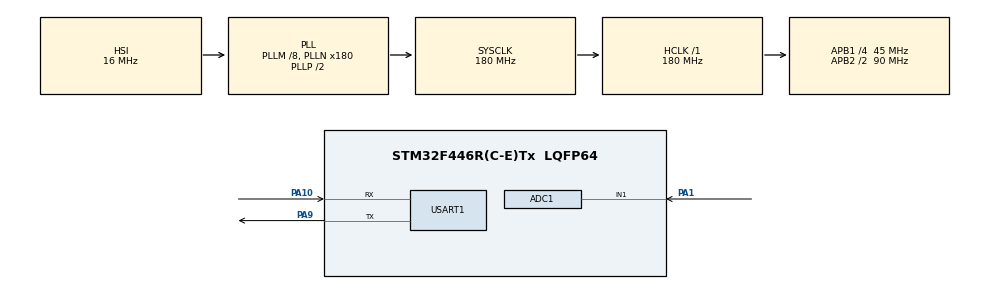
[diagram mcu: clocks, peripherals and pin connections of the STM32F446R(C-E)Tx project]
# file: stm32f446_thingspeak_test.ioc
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ADC1.Channel-0\#ChannelRegularConversion=ADC_CHANNEL_1
ADC1.NbrOfConversionFlag=1
ADC1.Rank-0\#ChannelRegularConversion=1
ADC1.SamplingTime-0\#ChannelRegularConversion=ADC_SAMPLETIME_3CYCLES
ADC1.master=1
Mcu.Family=STM32F4
Mcu.Name=STM32F446R(C-E)Tx
Mcu.Package=LQFP64
NVIC.PriorityGroup=NVIC_PRIORITYGROUP_4
NVIC.USART1_IRQn=true\:0\:0\:false\:false\:true\:true\:true
PA1.Signal=ADCx_IN1
PA10.Mode=Asynchronous
PA10.Signal=USART1_RX
PA9.Mode=Asynchronous
PA9.Signal=USART1_TX
PH0-OSC_IN.Mode=HSE-External-Clock-Source
PH0-OSC_IN.Signal=RCC_OSC_IN
PH1-OSC_OUT.Mode=HSE-External-Clock-Source
PH1-OSC_OUT.Signal=RCC_OSC_OUT
ProjectManager.HeapSize=0x200
ProjectManager.StackSize=0x400
ProjectManager.TargetToolchain=SW4STM32
RCC.AHBFreq_Value=180000000
RCC.APB1CLKDivider=RCC_HCLK_DIV4
RCC.APB1Freq_Value=45000000
RCC.APB1TimFreq_Value=90000000
RCC.APB2CLKDivider=RCC_HCLK_DIV2
RCC.APB2Freq_Value=90000000
RCC.APB2TimFreq_Value=180000000
RCC.CortexFreq_Value=180000000
RCC.HCLKFreq_Value=180000000
RCC.HSE_VALUE=8000000
RCC.PLLM=8
RCC.PLLN=180
RCC.SYSCLKFreq_VALUE=180000000
RCC.SYSCLKSource=RCC_SYSCLKSOURCE_PLLCLK
RCC.USBFreq_Value=180000000
RCC.VCOOutputFreq_Value=360000000
SH.ADCx_IN1.0=ADC1_IN1,IN1
USART1.VirtualMode=VM_ASYNC
board=custom

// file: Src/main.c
/* USER CODE BEGIN Header */
/**
 ******************************************************************************
 * @file           : main.c
 * @brief          : Main program body
 ******************************************************************************
 * @attention
 *
 * <h2><center>&copy; Copyright (c) 2020 STMicroelectronics.
 * All rights reserved.</center></h2>
 *
 * This software component is licensed by ST under BSD 3-Clause license,
 * the "License"; You may not use this file except in compliance with the
 * License. You may obtain a copy of the License at:
 *                        opensource.org/licenses/BSD-3-Clause
 *
 ******************************************************************************
 */
/* USER CODE END Header */

#include "main.h"
#include "ESPDataLogger.h"

ADC_HandleTypeDef hadc1;

UART_HandleTypeDef huart1;

void SystemClock_Config(void);
static void MX_GPIO_Init(void);
static void MX_ADC1_Init(void);
static void MX_USART1_UART_Init(void);

/* USER CODE BEGIN 0 */
uint16_t ADC_Get_Value(void) {
    uint16_t val = 0;
    HAL_ADC_Start(&hadc1);
    HAL_ADC_PollForConversion(&hadc1, 100);
    val = HAL_ADC_GetValue(&hadc1);
    HAL_ADC_Stop(&hadc1);
    return val;
}

float Voltage = 0;
uint16_t ADC_Value = 0;
uint8_t count = 0;

uint16_t Value_Buf[4];
/* USER CODE END 0 */

int main(void) {

    /* MCU Configuration--------------------------------------------------------*/

    /* Reset of all peripherals, Initializes the Flash interface and the Systick. */
    HAL_Init();

    /* Configure the system clock */
    SystemClock_Config();

    /* Initialize all configured peripherals */
    MX_GPIO_Init();
    MX_ADC1_Init();
    MX_USART1_UART_Init();
    /* USER CODE BEGIN 2 */
    ESP_Init("test", "12345678");

    /* USER CODE END 2 */

    /* Infinite loop */
    while (1) {

        /* USER CODE BEGIN 3 */

        ADC_Value = ADC_Get_Value();
        Voltage = ((float) ADC_Value * 5.0 / 1023);
        count++;

        Value_Buf[0] = ADC_Value;
        Value_Buf[1] = count;
        Value_Buf[2] = count * 2;
        Value_Buf[3] = Voltage;

        ESP_Send_Multi("KMFX6NJEQ3JRXF6M", 4, Value_Buf);

        HAL_Delay(15000); // must be at least 15 sec delay between 2 send
    }
    /* USER CODE END 3 */
}

void SystemClock_Config(void) {
    RCC_OscInitTypeDef RCC_OscInitStruct = { 0 };
    RCC_ClkInitTypeDef RCC_ClkInitStruct = { 0 };

    /** Configure the main internal regulator output voltage
     */
    __HAL_RCC_PWR_CLK_ENABLE()
    ;
    __HAL_PWR_VOLTAGESCALING_CONFIG(PWR_REGULATOR_VOLTAGE_SCALE1);
    /** Initializes the CPU, AHB and APB busses clocks
     */
    RCC_OscInitStruct.OscillatorType = RCC_OSCILLATORTYPE_HSI;
    RCC_OscInitStruct.HSIState = RCC_HSI_ON;
    RCC_OscInitStruct.HSICalibrationValue = RCC_HSICALIBRATION_DEFAULT;
    RCC_OscInitStruct.PLL.PLLState = RCC_PLL_ON;
    RCC_OscInitStruct.PLL.PLLSource = RCC_PLLSOURCE_HSI;
    RCC_OscInitStruct.PLL.PLLM = 8;
    RCC_OscInitStruct.PLL.PLLN = 180;
    RCC_OscInitStruct.PLL.PLLP = RCC_PLLP_DIV2;
    RCC_OscInitStruct.PLL.PLLQ = 2;
    RCC_OscInitStruct.PLL.PLLR = 2;
    if (HAL_RCC_OscConfig(&RCC_OscInitStruct) != HAL_OK) {
        Error_Handler();
    }
    /** Activate the Over-Drive mode
     */
    if (HAL_PWREx_EnableOverDrive() != HAL_OK) {
        Error_Handler();
    }
    /** Initializes the CPU, AHB and APB busses clocks
     */
    RCC_ClkInitStruct.ClockType = RCC_CLOCKTYPE_HCLK | RCC_CLOCKTYPE_SYSCLK
            | RCC_CLOCKTYPE_PCLK1 | RCC_CLOCKTYPE_PCLK2;
    RCC_ClkInitStruct.SYSCLKSource = RCC_SYSCLKSOURCE_PLLCLK;
    RCC_ClkInitStruct.AHBCLKDivider = RCC_SYSCLK_DIV1;
    RCC_ClkInitStruct.APB1CLKDivider = RCC_HCLK_DIV4;
    RCC_ClkInitStruct.APB2CLKDivider = RCC_HCLK_DIV2;

    if (HAL_RCC_ClockConfig(&RCC_ClkInitStruct, FLASH_LATENCY_5) != HAL_OK) {
        Error_Handler();
    }
}

static void MX_ADC1_Init(void) {

    ADC_ChannelConfTypeDef sConfig = { 0 };

    /** Configure the global features of the ADC (Clock, Resolution, Data Alignment and number of conversion)
     */
    hadc1.Instance = ADC1;
    hadc1.Init.ClockPrescaler = ADC_CLOCK_SYNC_PCLK_DIV4;
    hadc1.Init.Resolution = ADC_RESOLUTION_12B;
    hadc1.Init.ScanConvMode = DISABLE;
    hadc1.Init.ContinuousConvMode = DISABLE;
    hadc1.Init.DiscontinuousConvMode = DISABLE;
    hadc1.Init.ExternalTrigConvEdge = ADC_EXTERNALTRIGCONVEDGE_NONE;
    hadc1.Init.ExternalTrigConv = ADC_SOFTWARE_START;
    hadc1.Init.DataAlign = ADC_DATAALIGN_RIGHT;
    hadc1.Init.NbrOfConversion = 1;
    hadc1.Init.DMAContinuousRequests = DISABLE;
    hadc1.Init.EOCSelection = ADC_EOC_SINGLE_CONV;
    if (HAL_ADC_Init(&hadc1) != HAL_OK) {
        Error_Handler();
    }
    /** Configure for the selected ADC regular channel its corresponding rank in the sequencer and its sample time.
     */
    sConfig.Channel = ADC_CHANNEL_1;
    sConfig.Rank = 1;
    sConfig.SamplingTime = ADC_SAMPLETIME_3CYCLES;
    if (HAL_ADC_ConfigChannel(&hadc1, &sConfig) != HAL_OK) {
        Error_Handler();
    }

}

static void MX_USART1_UART_Init(void) {

    huart1.Instance = USART1;
    huart1.Init.BaudRate = 115200;
    huart1.Init.WordLength = UART_WORDLENGTH_8B;
    huart1.Init.StopBits = UART_STOPBITS_1;
    huart1.Init.Parity = UART_PARITY_NONE;
    huart1.Init.Mode = UART_MODE_TX_RX;
    huart1.Init.HwFlowCtl = UART_HWCONTROL_NONE;
    huart1.Init.OverSampling = UART_OVERSAMPLING_16;
    if (HAL_UART_Init(&huart1) != HAL_OK) {
        Error_Handler();
    }

}

static void MX_GPIO_Init(void) {

    /* GPIO Ports Clock Enable */
    __HAL_RCC_GPIOH_CLK_ENABLE()
    ;
    __HAL_RCC_GPIOA_CLK_ENABLE()
    ;

}

void Error_Handler(void) {
}

/************************ (C) COPYRIGHT STMicroelectronics *****END OF FILE****/
